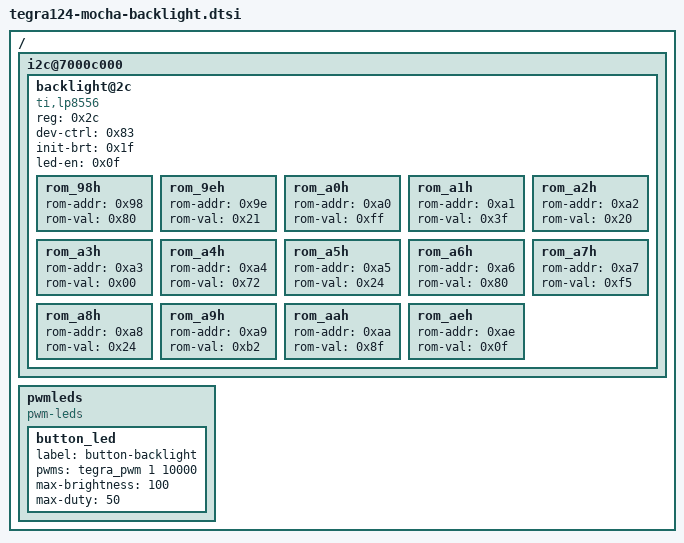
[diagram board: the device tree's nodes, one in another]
/ {
	i2c@7000c000 {
		backlight@2c {
			compatible = "ti,lp8556";
			reg = <0x2c>;

			dev-ctrl = /bits/ 8 <0x83>;
			init-brt = /bits/ 8 <0x1f>;
			led-en   = /bits/ 8 <0x0f>;

			rom_98h {
				rom-addr = /bits/ 8 <0x98>;
				rom-val = /bits/ 8 <0x80>;
			};
			rom_9eh {
				rom-addr = /bits/ 8 <0x9e>;
				rom-val = /bits/ 8 <0x21>;
			};
			rom_a0h {
				rom-addr = /bits/ 8 <0xa0>;
				rom-val = /bits/ 8 <0xff>;
			};
			rom_a1h {
				rom-addr = /bits/ 8 <0xa1>;
				rom-val = /bits/ 8 <0x3f>;
			};
			rom_a2h {
				rom-addr = /bits/ 8 <0xa2>;
				rom-val = /bits/ 8 <0x20>;
			};
			rom_a3h {
				rom-addr = /bits/ 8 <0xa3>;
				rom-val = /bits/ 8 <0x00>;
			};
			rom_a4h {
				rom-addr = /bits/ 8 <0xa4>;
				rom-val = /bits/ 8 <0x72>;
			};
			rom_a5h {
				rom-addr = /bits/ 8 <0xa5>;
				rom-val = /bits/ 8 <0x24>;
			};
			rom_a6h {
				rom-addr = /bits/ 8 <0xa6>;
				rom-val = /bits/ 8 <0x80>;
			};
			rom_a7h {
				rom-addr = /bits/ 8 <0xa7>;
				rom-val = /bits/ 8 <0xf5>;
			};
			rom_a8h {
				rom-addr = /bits/ 8 <0xa8>;
				rom-val = /bits/ 8 <0x24>;
			};
			rom_a9h {
				rom-addr = /bits/ 8 <0xa9>;
				rom-val = /bits/ 8 <0xb2>;
			};
			rom_aah {
				rom-addr = /bits/ 8 <0xaa>;
				rom-val = /bits/ 8 <0x8f>;
			};
			rom_aeh {
				rom-addr = /bits/ 8 <0xae>;
				rom-val = /bits/ 8 <0x0f>;
			};
		};
	};

	pwmleds {
		compatible = "pwm-leds";
		button_led {
			label = "button-backlight";
			pwms = <&tegra_pwm 1 10000>;
			max-brightness = <100>;
			max-duty = <50>;
		};
	};
};
